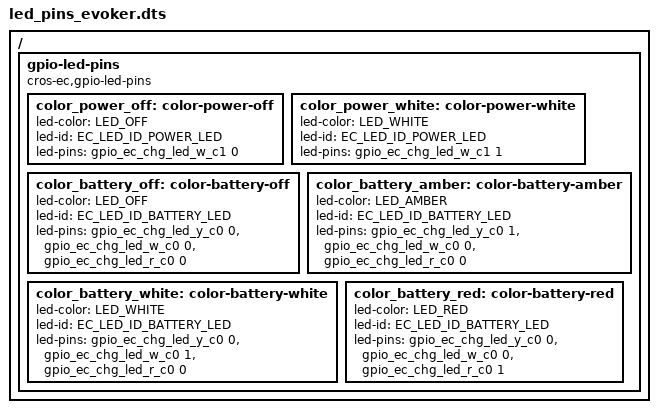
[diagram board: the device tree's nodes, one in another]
/* Copyright 2022 The ChromiumOS Authors
 * Use of this source code is governed by a BSD-style license that can be
 * found in the LICENSE file.
 */

/ {
	gpio-led-pins {
		compatible = "cros-ec,gpio-led-pins";

		color_power_off: color-power-off {
			led-color = "LED_OFF";
			led-id = "EC_LED_ID_POWER_LED";
			led-pins = <&gpio_ec_chg_led_w_c1 0>;
		};

		color_power_white: color-power-white {
			led-color = "LED_WHITE";
			led-id = "EC_LED_ID_POWER_LED";
			led-pins = <&gpio_ec_chg_led_w_c1 1>;
		};

		color_battery_off: color-battery-off {
			led-color = "LED_OFF";
			led-id = "EC_LED_ID_BATTERY_LED";
			led-pins = <&gpio_ec_chg_led_y_c0 0>,
				   <&gpio_ec_chg_led_w_c0 0>,
				   <&gpio_ec_chg_led_r_c0 0>;
		};

		color_battery_amber: color-battery-amber {
			led-color = "LED_AMBER";
			led-id = "EC_LED_ID_BATTERY_LED";
			led-pins = <&gpio_ec_chg_led_y_c0 1>,
				   <&gpio_ec_chg_led_w_c0 0>,
				   <&gpio_ec_chg_led_r_c0 0>;
		};

		color_battery_white: color-battery-white {
			led-color = "LED_WHITE";
			led-id = "EC_LED_ID_BATTERY_LED";
			led-pins = <&gpio_ec_chg_led_y_c0 0>,
				   <&gpio_ec_chg_led_w_c0 1>,
				   <&gpio_ec_chg_led_r_c0 0>;
		};

		color_battery_red: color-battery-red {
			led-color = "LED_RED";
			led-id = "EC_LED_ID_BATTERY_LED";
			led-pins = <&gpio_ec_chg_led_y_c0 0>,
				   <&gpio_ec_chg_led_w_c0 0>,
				   <&gpio_ec_chg_led_r_c0 1>;
		};
	};
};
